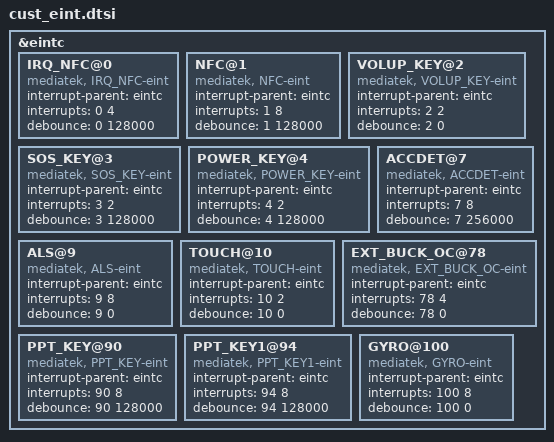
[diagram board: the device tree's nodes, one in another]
/*
 * Generated by MTK SP DrvGen Version 03.13.6 for MT6735M. Copyright MediaTek Inc. (C) 2013.
 * Thu Nov 07 11:17:41 2019
 * Do Not Modify the File.
 */

/*************************
 * EINT DTSI File
*************************/

&eintc {
	IRQ_NFC@0 {
		compatible = "mediatek, IRQ_NFC-eint";
		interrupt-parent = <&eintc>;
		interrupts = <0 4>;
		debounce = <0 128000>;
	};

	NFC@1 {
		compatible = "mediatek, NFC-eint";
		interrupt-parent = <&eintc>;
		interrupts = <1 8>;
		debounce = <1 128000>;
	};

	VOLUP_KEY@2 {
		compatible = "mediatek, VOLUP_KEY-eint";
		interrupt-parent = <&eintc>;
		interrupts = <2 2>;
		debounce = <2 0>;
	};

	SOS_KEY@3 {
		compatible = "mediatek, SOS_KEY-eint";
		interrupt-parent = <&eintc>;
		interrupts = <3 2>;
		debounce = <3 128000>;
	};

	POWER_KEY@4 {
		compatible = "mediatek, POWER_KEY-eint";
		interrupt-parent = <&eintc>;
		interrupts = <4 2>;
		debounce = <4 128000>;
	};

	ACCDET@7 {
		compatible = "mediatek, ACCDET-eint";
		interrupt-parent = <&eintc>;
		interrupts = <7 8>;
		debounce = <7 256000>;
	};

	ALS@9 {
		compatible = "mediatek, ALS-eint";
		interrupt-parent = <&eintc>;
		interrupts = <9 8>;
		debounce = <9 0>;
	};

	TOUCH@10 {
		compatible = "mediatek, TOUCH-eint";
		interrupt-parent = <&eintc>;
		interrupts = <10 2>;
		debounce = <10 0>;
	};

	EXT_BUCK_OC@78 {
		compatible = "mediatek, EXT_BUCK_OC-eint";
		interrupt-parent = <&eintc>;
		interrupts = <78 4>;
		debounce = <78 0>;
	};

	PPT_KEY@90 {
		compatible = "mediatek, PPT_KEY-eint";
		interrupt-parent = <&eintc>;
		interrupts = <90 8>;
		debounce = <90 128000>;
	};

	PPT_KEY1@94 {
		compatible = "mediatek, PPT_KEY1-eint";
		interrupt-parent = <&eintc>;
		interrupts = <94 8>;
		debounce = <94 128000>;
	};

	GYRO@100 {
		compatible = "mediatek, GYRO-eint";
		interrupt-parent = <&eintc>;
		interrupts = <100 8>;
		debounce = <100 0>;
	};

};
